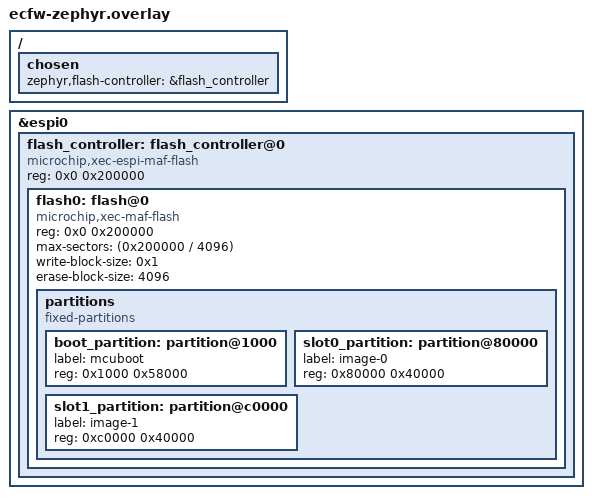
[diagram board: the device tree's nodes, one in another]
/*
 * Copyright (c) 2020 Nordic Semiconductor ASA
 *
 * SPDX-License-Identifier: Apache-2.0
 */

/delete-node/ &flash0;
/ {
	chosen {
		zephyr,flash-controller = &flash_controller;
/*		zephyr,code-partition = &slot0_partition; */
	};
};

&espi0 {
	flash_controller: flash_controller@0 {
		compatible = "microchip,xec-espi-maf-flash";
		reg = < 0x0 0x200000 >;
		#address-cells = < 0x1 >;
		#size-cells = < 0x1 >;
		flash0: flash@0 {
			compatible = "microchip,xec-maf-flash","soc-nv-flash";
			reg = < 0x0 0x200000 >;
			max-sectors = < (0x200000 / 4096) >;
			write-block-size = < 0x1 >;
			erase-block-size = < 4096 >;
			partitions {
				compatible = "fixed-partitions";
				#address-cells = < 0x1 >;
				#size-cells = < 0x1 >;
				boot_partition: partition@1000 {
					label = "mcuboot";
					reg = < 0x1000 0x58000 >;
				};
				slot0_partition: partition@80000 {
					label = "image-0";
					reg = < 0x80000 0x40000 >;
				};
				slot1_partition: partition@c0000 {
					label = "image-1";
					reg = < 0xc0000 0x40000 >;
				};
			};
		};
	};
};
